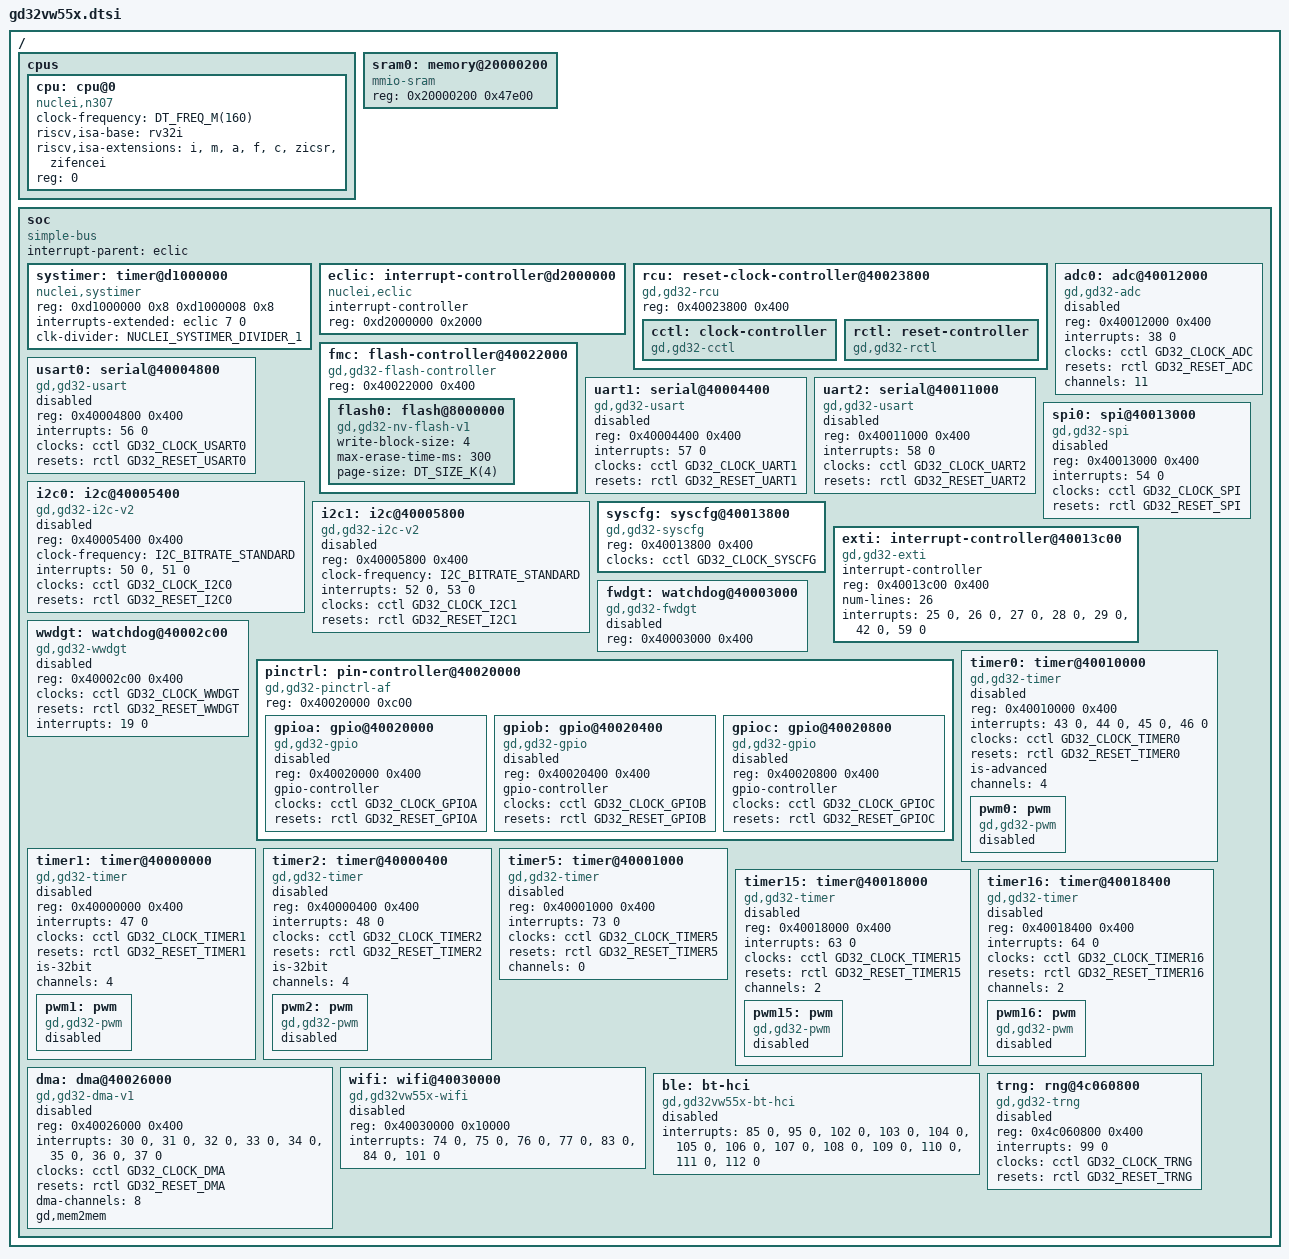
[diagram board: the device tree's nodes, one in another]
/*
 * Copyright (c) 2026 Jorge Guzman
 *
 * SPDX-License-Identifier: Apache-2.0
 */

#include <freq.h>
#include <mem.h>
#include <zephyr/dt-bindings/gpio/gpio.h>
#include <zephyr/dt-bindings/timer/nuclei-systimer.h>
#include <zephyr/dt-bindings/i2c/i2c.h>
#include <zephyr/dt-bindings/pwm/pwm.h>
#include <zephyr/dt-bindings/clock/gd32vw55x-clocks.h>
#include <zephyr/dt-bindings/reset/gd32vw55x.h>

/ {
	#address-cells = <1>;
	#size-cells = <1>;

	cpus {
		#address-cells = <1>;
		#size-cells = <0>;

		cpu: cpu@0 {
			clock-frequency = <DT_FREQ_M(160)>;
			compatible = "nuclei,n307", "riscv";
			riscv,isa-base = "rv32i";
			riscv,isa-extensions = "i", "m", "a", "f", "c",
					       "zicsr", "zifencei";
			reg = <0>;
		};
	};

	/* The first 0x200 bytes of SRAM belong to the mask ROM scratch
	 * area and the top 32 KB are shared with the Wi-Fi MAC RX buffers,
	 * exactly as in the vendor SDK linker scripts.
	 */
	sram0: memory@20000200 {
		compatible = "mmio-sram";
		reg = <0x20000200 0x47e00>;
	};

	soc {
		#address-cells = <1>;
		#size-cells = <1>;
		compatible = "simple-bus";
		interrupt-parent = <&eclic>;
		ranges;

		systimer: timer@d1000000 {
			compatible = "nuclei,systimer", "riscv,machine-timer";
			reg = <0xd1000000 0x8 0xd1000008 0x8>;
			reg-names = "mtime", "mtimecmp";
			interrupts-extended = <&eclic 7 0>;
			clk-divider = <NUCLEI_SYSTIMER_DIVIDER_1>;
		};

		eclic: interrupt-controller@d2000000 {
			compatible = "nuclei,eclic";
			#address-cells = <0>;
			#interrupt-cells = <2>;
			interrupt-controller;
			reg = <0xd2000000 0x2000>;
		};

		rcu: reset-clock-controller@40023800 {
			compatible = "gd,gd32-rcu";
			reg = <0x40023800 0x400>;
			status = "okay";

			cctl: clock-controller {
				compatible = "gd,gd32-cctl";
				#clock-cells = <1>;
				status = "okay";
			};

			rctl: reset-controller {
				compatible = "gd,gd32-rctl";
				#reset-cells = <1>;
				status = "okay";
			};
		};

		fmc: flash-controller@40022000 {
			compatible = "gd,gd32-flash-controller";
			reg = <0x40022000 0x400>;
			ranges;
			#address-cells = <1>;
			#size-cells = <1>;

			flash0: flash@8000000 {
				compatible = "gd,gd32-nv-flash-v1", "soc-nv-flash";
				write-block-size = <4>;
				max-erase-time-ms = <300>;
				page-size = <DT_SIZE_K(4)>;
				#address-cells = <1>;
				#size-cells = <1>;
			};
		};

		usart0: serial@40004800 {
			compatible = "gd,gd32-usart";
			reg = <0x40004800 0x400>;
			interrupts = <56 0>;
			clocks = <&cctl GD32_CLOCK_USART0>;
			resets = <&rctl GD32_RESET_USART0>;
			status = "disabled";
		};

		uart1: serial@40004400 {
			compatible = "gd,gd32-usart";
			reg = <0x40004400 0x400>;
			interrupts = <57 0>;
			clocks = <&cctl GD32_CLOCK_UART1>;
			resets = <&rctl GD32_RESET_UART1>;
			status = "disabled";
		};

		uart2: serial@40011000 {
			compatible = "gd,gd32-usart";
			reg = <0x40011000 0x400>;
			interrupts = <58 0>;
			clocks = <&cctl GD32_CLOCK_UART2>;
			resets = <&rctl GD32_RESET_UART2>;
			status = "disabled";
		};

		adc0: adc@40012000 {
			compatible = "gd,gd32-adc";
			reg = <0x40012000 0x400>;
			interrupts = <38 0>;
			clocks = <&cctl GD32_CLOCK_ADC>;
			resets = <&rctl GD32_RESET_ADC>;
			channels = <11>;
			status = "disabled";
			#io-channel-cells = <1>;
		};

		i2c0: i2c@40005400 {
			compatible = "gd,gd32-i2c-v2";
			reg = <0x40005400 0x400>;
			#address-cells = <1>;
			#size-cells = <0>;
			clock-frequency = <I2C_BITRATE_STANDARD>;
			interrupts = <50 0>, <51 0>;
			interrupt-names = "event", "error";
			clocks = <&cctl GD32_CLOCK_I2C0>;
			resets = <&rctl GD32_RESET_I2C0>;
			status = "disabled";
		};

		i2c1: i2c@40005800 {
			compatible = "gd,gd32-i2c-v2";
			reg = <0x40005800 0x400>;
			#address-cells = <1>;
			#size-cells = <0>;
			clock-frequency = <I2C_BITRATE_STANDARD>;
			interrupts = <52 0>, <53 0>;
			interrupt-names = "event", "error";
			clocks = <&cctl GD32_CLOCK_I2C1>;
			resets = <&rctl GD32_RESET_I2C1>;
			status = "disabled";
		};

		spi0: spi@40013000 {
			compatible = "gd,gd32-spi";
			reg = <0x40013000 0x400>;
			interrupts = <54 0>;
			clocks = <&cctl GD32_CLOCK_SPI>;
			resets = <&rctl GD32_RESET_SPI>;
			status = "disabled";
			#address-cells = <1>;
			#size-cells = <0>;
		};

		syscfg: syscfg@40013800 {
			compatible = "gd,gd32-syscfg";
			reg = <0x40013800 0x400>;
			clocks = <&cctl GD32_CLOCK_SYSCFG>;
			status = "okay";
		};

		exti: interrupt-controller@40013c00 {
			compatible = "gd,gd32-exti";
			#address-cells = <0>;
			interrupt-controller;
			#interrupt-cells = <1>;
			reg = <0x40013c00 0x400>;
			num-lines = <26>;
			interrupts = <25 0>, <26 0>, <27 0>, <28 0>, <29 0>,
				     <42 0>, <59 0>;
			interrupt-names = "line0", "line1", "line2", "line3",
					  "line4", "line5-9", "line10-15";
			status = "okay";
		};

		fwdgt: watchdog@40003000 {
			compatible = "gd,gd32-fwdgt";
			reg = <0x40003000 0x400>;
			status = "disabled";
		};

		wwdgt: watchdog@40002c00 {
			compatible = "gd,gd32-wwdgt";
			reg = <0x40002c00 0x400>;
			clocks = <&cctl GD32_CLOCK_WWDGT>;
			resets = <&rctl GD32_RESET_WWDGT>;
			interrupts = <19 0>;
			status = "disabled";
		};

		pinctrl: pin-controller@40020000 {
			compatible = "gd,gd32-pinctrl-af";
			reg = <0x40020000 0xc00>;
			#address-cells = <1>;
			#size-cells = <1>;
			status = "okay";

			gpioa: gpio@40020000 {
				compatible = "gd,gd32-gpio";
				reg = <0x40020000 0x400>;
				gpio-controller;
				#gpio-cells = <2>;
				clocks = <&cctl GD32_CLOCK_GPIOA>;
				resets = <&rctl GD32_RESET_GPIOA>;
				status = "disabled";
			};

			gpiob: gpio@40020400 {
				compatible = "gd,gd32-gpio";
				reg = <0x40020400 0x400>;
				gpio-controller;
				#gpio-cells = <2>;
				clocks = <&cctl GD32_CLOCK_GPIOB>;
				resets = <&rctl GD32_RESET_GPIOB>;
				status = "disabled";
			};

			gpioc: gpio@40020800 {
				compatible = "gd,gd32-gpio";
				reg = <0x40020800 0x400>;
				gpio-controller;
				#gpio-cells = <2>;
				clocks = <&cctl GD32_CLOCK_GPIOC>;
				resets = <&rctl GD32_RESET_GPIOC>;
				status = "disabled";
			};
		};

		timer0: timer@40010000 {
			compatible = "gd,gd32-timer";
			reg = <0x40010000 0x400>;
			interrupts = <43 0>, <44 0>, <45 0>, <46 0>;
			interrupt-names = "brk", "up", "trgcom", "cc";
			clocks = <&cctl GD32_CLOCK_TIMER0>;
			resets = <&rctl GD32_RESET_TIMER0>;
			is-advanced;
			channels = <4>;
			status = "disabled";

			pwm0: pwm {
				compatible = "gd,gd32-pwm";
				status = "disabled";
				#pwm-cells = <3>;
			};
		};

		timer1: timer@40000000 {
			compatible = "gd,gd32-timer";
			reg = <0x40000000 0x400>;
			interrupts = <47 0>;
			interrupt-names = "global";
			clocks = <&cctl GD32_CLOCK_TIMER1>;
			resets = <&rctl GD32_RESET_TIMER1>;
			is-32bit;
			channels = <4>;
			status = "disabled";

			pwm1: pwm {
				compatible = "gd,gd32-pwm";
				status = "disabled";
				#pwm-cells = <3>;
			};
		};

		timer2: timer@40000400 {
			compatible = "gd,gd32-timer";
			reg = <0x40000400 0x400>;
			interrupts = <48 0>;
			interrupt-names = "global";
			clocks = <&cctl GD32_CLOCK_TIMER2>;
			resets = <&rctl GD32_RESET_TIMER2>;
			is-32bit;
			channels = <4>;
			status = "disabled";

			pwm2: pwm {
				compatible = "gd,gd32-pwm";
				status = "disabled";
				#pwm-cells = <3>;
			};
		};

		timer5: timer@40001000 {
			compatible = "gd,gd32-timer";
			reg = <0x40001000 0x400>;
			interrupts = <73 0>;
			interrupt-names = "global";
			clocks = <&cctl GD32_CLOCK_TIMER5>;
			resets = <&rctl GD32_RESET_TIMER5>;
			channels = <0>;
			status = "disabled";
		};

		timer15: timer@40018000 {
			compatible = "gd,gd32-timer";
			reg = <0x40018000 0x400>;
			interrupts = <63 0>;
			interrupt-names = "global";
			clocks = <&cctl GD32_CLOCK_TIMER15>;
			resets = <&rctl GD32_RESET_TIMER15>;
			channels = <2>;
			status = "disabled";

			pwm15: pwm {
				compatible = "gd,gd32-pwm";
				status = "disabled";
				#pwm-cells = <3>;
			};
		};

		timer16: timer@40018400 {
			compatible = "gd,gd32-timer";
			reg = <0x40018400 0x400>;
			interrupts = <64 0>;
			interrupt-names = "global";
			clocks = <&cctl GD32_CLOCK_TIMER16>;
			resets = <&rctl GD32_RESET_TIMER16>;
			channels = <2>;
			status = "disabled";

			pwm16: pwm {
				compatible = "gd,gd32-pwm";
				status = "disabled";
				#pwm-cells = <3>;
			};
		};

		dma: dma@40026000 {
			compatible = "gd,gd32-dma-v1";
			reg = <0x40026000 0x400>;
			interrupts = <30 0>, <31 0>, <32 0>, <33 0>,
				     <34 0>, <35 0>, <36 0>, <37 0>;
			clocks = <&cctl GD32_CLOCK_DMA>;
			resets = <&rctl GD32_RESET_DMA>;
			dma-channels = <8>;
			gd,mem2mem;
			#dma-cells = <4>;
			status = "disabled";
		};

		wifi: wifi@40030000 {
			compatible = "gd,gd32vw55x-wifi";
			reg = <0x40030000 0x10000>;
			interrupts = <74 0>, <75 0>, <76 0>, <77 0>,
				     <83 0>, <84 0>, <101 0>;
			interrupt-names = "prot", "intgen", "tx", "rx",
					  "la", "wkup", "int";
			status = "disabled";
		};

		ble: bt-hci {
			compatible = "gd,gd32vw55x-bt-hci";
			interrupts = <85 0>, <95 0>, <102 0>, <103 0>,
				     <104 0>, <105 0>, <106 0>, <107 0>,
				     <108 0>, <109 0>, <110 0>, <111 0>,
				     <112 0>;
			interrupt-names = "wkup", "power_status", "sw_trig",
					  "fine_timer", "stamp1", "stamp2",
					  "stamp3", "enc_engine", "sleep_mode",
					  "half_slot", "fifo", "error",
					  "freq_select";
			status = "disabled";
		};

		trng: rng@4c060800 {
			compatible = "gd,gd32-trng";
			reg = <0x4c060800 0x400>;
			interrupts = <99 0>;
			clocks = <&cctl GD32_CLOCK_TRNG>;
			resets = <&rctl GD32_RESET_TRNG>;
			status = "disabled";
		};
	};
};
